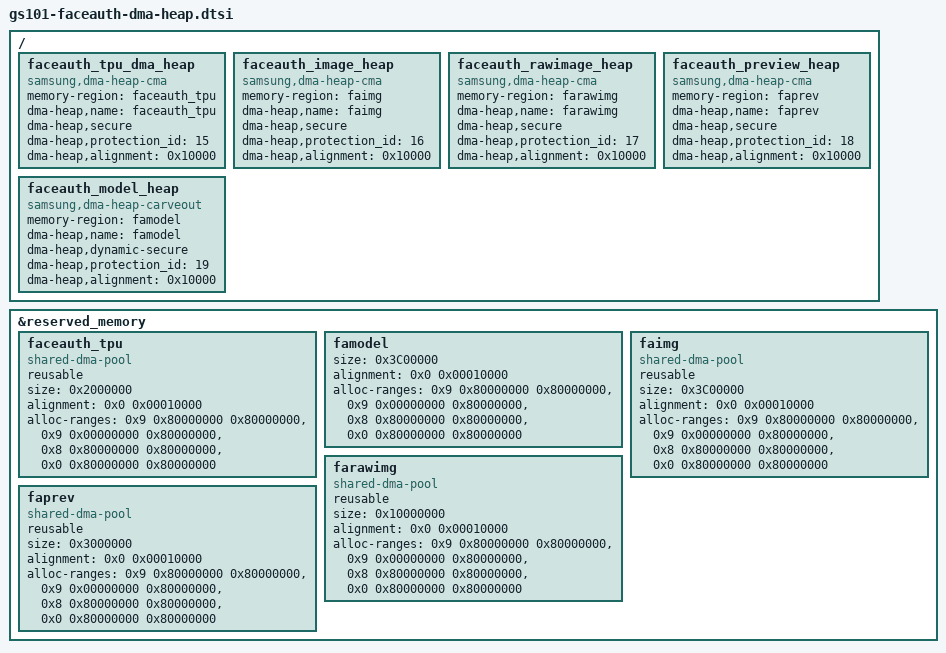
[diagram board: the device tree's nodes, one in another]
// SPDX-License-Identifier: GPL-2.0
/*
 * GS101 SoC Faceauth-HEAP
 *
 * Copyright 2021 Google LLC
 */

/ {
	faceauth_tpu_dma_heap {
		compatible = "samsung,dma-heap-cma";
		memory-region = <&faceauth_tpu>;
		dma-heap,name = "faceauth_tpu";
		dma-heap,secure;
		dma-heap,protection_id = <15>;
		dma-heap,alignment = <0x10000>;
	};

	faceauth_image_heap {
		compatible = "samsung,dma-heap-cma";
		memory-region = <&faimg>;
		dma-heap,name = "faimg";
		dma-heap,secure;
		dma-heap,protection_id = <16>;
		dma-heap,alignment = <0x10000>;
	};

	faceauth_rawimage_heap {
		compatible = "samsung,dma-heap-cma";
		memory-region = <&farawimg>;
		dma-heap,name = "farawimg";
		dma-heap,secure;
		dma-heap,protection_id = <17>;
		dma-heap,alignment = <0x10000>;
	};

	faceauth_preview_heap {
		compatible = "samsung,dma-heap-cma";
		memory-region = <&faprev>;
		dma-heap,name = "faprev";
		dma-heap,secure;
		dma-heap,protection_id = <18>;
		dma-heap,alignment = <0x10000>;
	};

	faceauth_model_heap {
		compatible = "samsung,dma-heap-carveout";
		memory-region = <&famodel>;
		dma-heap,name = "famodel";
		dma-heap,dynamic-secure;
		dma-heap,protection_id = <19>;
		dma-heap,alignment = <0x10000>;
	};
};

&reserved_memory {
	#address-cells = <2>;
	#size-cells = <1>;

	faceauth_tpu: faceauth_tpu {
		compatible = "shared-dma-pool";
		reusable;
		size = <0x2000000>;
		alignment = <0x0 0x00010000>;
		alloc-ranges = <0x9 0x80000000 0x80000000>,
			       <0x9 0x00000000 0x80000000>,
			       <0x8 0x80000000 0x80000000>,
			       <0x0 0x80000000 0x80000000>;
	};

	famodel: famodel {
		size = <0x3C00000>;
		alignment = <0x0 0x00010000>;
		alloc-ranges = <0x9 0x80000000 0x80000000>,
			       <0x9 0x00000000 0x80000000>,
			       <0x8 0x80000000 0x80000000>,
			       <0x0 0x80000000 0x80000000>;
	};

	faimg: faimg {
		compatible = "shared-dma-pool";
		reusable;
		size = <0x3C00000>;
		alignment = <0x0 0x00010000>;
		alloc-ranges = <0x9 0x80000000 0x80000000>,
			       <0x9 0x00000000 0x80000000>,
			       <0x8 0x80000000 0x80000000>,
			       <0x0 0x80000000 0x80000000>;
	};

	farawimg: farawimg {
		compatible = "shared-dma-pool";
		reusable;
		size = <0x10000000>;
		alignment = <0x0 0x00010000>;
		alloc-ranges = <0x9 0x80000000 0x80000000>,
			       <0x9 0x00000000 0x80000000>,
			       <0x8 0x80000000 0x80000000>,
			       <0x0 0x80000000 0x80000000>;
	};

	faprev: faprev {
		compatible = "shared-dma-pool";
		reusable;
		size = <0x3000000>;
		alignment = <0x0 0x00010000>;
		alloc-ranges = <0x9 0x80000000 0x80000000>,
			       <0x9 0x00000000 0x80000000>,
			       <0x8 0x80000000 0x80000000>,
			       <0x0 0x80000000 0x80000000>;
	};
};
